# R7FA4T1BB register map
Vendor: Renesas Electronics Corporation; Series: RA4; File version: 1.20.00
CPU: CM33 r0p4, little endian, MPU, FPU, VTOR, 4 interrupt priority bits, 96 interrupts
Registers are 32-bit, read-write, reset 0x0 unless marked. A register's access mark holds for its fields unless they carry their own. Offsets are from the block's base; [hi:lo] are bit positions; 'fields as' and 'values as' point back to an identical list.

## POEG — Port Output Enable Module for GPT
Base 0x4008A000
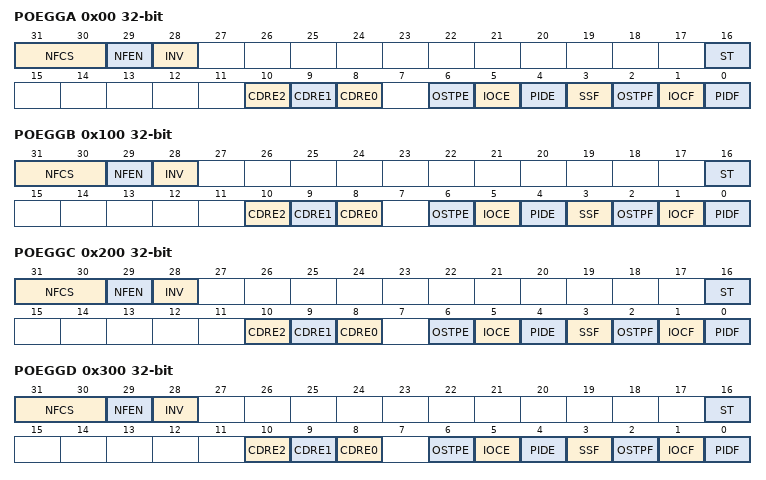
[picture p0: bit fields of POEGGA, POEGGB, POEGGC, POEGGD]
0x00 POEGGA — POEG Group A Setting Register
  [31:30] NFCS — Noise Filter Clock Select
  [29] NFEN — Noise Filter Enable
  [28] INV — GTETRGn Input Reverse
  [16] ST ro — GTETRGn Input Status Flag
  [10] CDRE2
  [9] CDRE1
  [8] CDRE0
  [6] OSTPE — Oscillation Stop Detection Enable
  [5] IOCE — Enable for GPT Output,Disable Request
  [4] PIDE — Port Input Detection Enable
  [3] SSF — Software Stop Flag
  [2] OSTPF — Oscillation Stop Detection Flag
  [1] IOCF — Detection Flag for GPT Output,Disable Request
  [0] PIDF — Port Input Detection Flag
0x100 POEGGB — POEG Group B Setting Register
  fields as POEGGA
0x200 POEGGC — POEG Group C Setting Register
  fields as POEGGA
0x300 POEGGD — POEG Group D Setting Register
  fields as POEGGA

## PSCU — Peripheral Security Control Unit
Base 0x400E0000
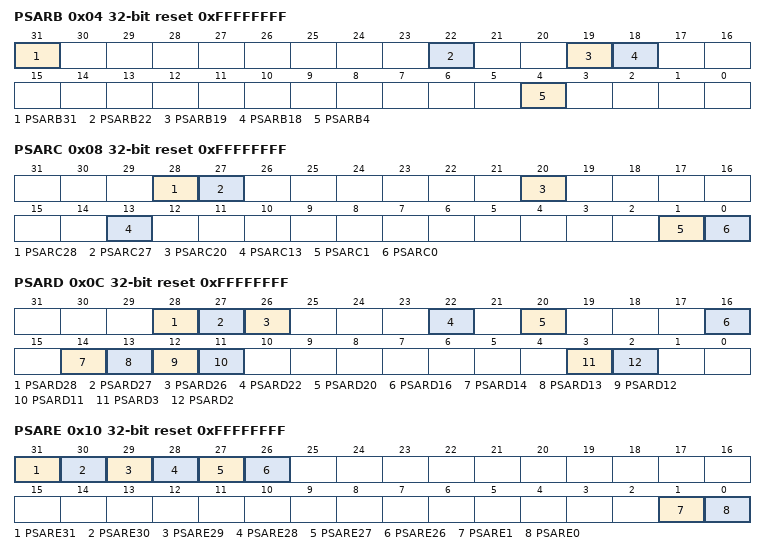
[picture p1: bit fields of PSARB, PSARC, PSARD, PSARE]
0x04 PSARB reset 0xFFFFFFFF — Peripheral Security Attribution Register B
  [31] PSARB31 — SCI0 and the MSTPCRB.MSTPB31 bit security attribution
  [22] PSARB22 — SCI9 and the MSTPCRB.MSTPB22 bit security attribution
  [19] PSARB19 — SPI0 and the MSTPCRB.MSTPB19 bit security attribution
  [18] PSARB18 — SPI1 and the MSTPCRB.MSTPB18 bit security attribution
  [4] PSARB4 — I3C and the MSTPCRB.MSTPB4 bit security attribution
0x08 PSARC reset 0xFFFFFFFF — Peripheral Security Attribution Register C
  [28] PSARC28 — TRNG and the MSTPCRC.MSTPC28 bit security attribution
  [27] PSARC27 — CANFD0 and the MSTPCRC.MSTPC27 bit security attribution
  [20] PSARC20 — TFU and the MSTPCRC.MSTPC20 bit security attribution
  [13] PSARC13 — DOC and the MSTPCRC.MSTPC13 bit security attribution
  [1] PSARC1 — CRC and the MSTPCRC.MSTPC1 bit security attribution
  [0] PSARC0 — CAC and the MSTPCRC.MSTPC0 bit security attribution
0x0C PSARD reset 0xFFFFFFFF — Peripheral Security Attribution Register D
  [28] PSARD28 — ACMPHS0 and the MSTPCRD.MSTPD28 bit security attribution
  [27] PSARD27 — ACMPHS1 and the MSTPCRD.MSTPD27 bit security attribution
  [26] PSARD26 — ACMPHS2 and the MSTPCRD.MSTPD26 bit security attribution
  [22] PSARD22 — TSN and the MSTPCRD.MSTPD22 bit security attribution
  [20] PSARD20 — DAC12 and the MSTPCRD.MSTPD20 bit security attribution
  [16] PSARD16 — ADC120 and the MSTPCRD.MSTPD16 bit security attribution
  [14] PSARD14 — POEG Group A and the MSTPCRD.MSTPD14 bit security attribution
  [13] PSARD13 — POEG Group B and the MSTPCRD.MSTPD13 bit security attribution
  [12] PSARD12 — POEG Group C and the MSTPCRD.MSTPD12 bit security attribution
  [11] PSARD11 — POEG Group D and the MSTPCRD.MSTPD11 bit security attribution
  [3] PSARD3 — AGT0 and the MSTPCRD.MSTPD3 bit security attribution
  [2] PSARD2 — AGT1 and the MSTPCRD.MSTPD2 bit security attribution
0x10 PSARE reset 0xFFFFFFFF — Peripheral Security Attribution Register E
  [31] PSARE31 — GPT0, GPT_OPS and the MSTPCRE.MSTPE31 bit security attribution
  [30] PSARE30 — GPT1 and the MSTPCRE.MSTPE30 bit security attribution
  [29] PSARE29 — GPT2 and the MSTPCRE.MSTPE29 bit security attribution
  [28] PSARE28 — GPT3 and the MSTPCRE.MSTPE28 bit security attribution
  [27] PSARE27 — GPT4 and the MSTPCRE.MSTPE27 bit security attribution
  [26] PSARE26 — GPT5 and the MSTPCRE.MSTPE26 bit security attribution
  [1] PSARE1 — IWDT security attribution
  [0] PSARE0 — WDT security attribution
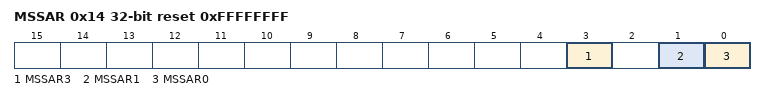
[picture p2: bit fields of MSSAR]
0x14 MSSAR reset 0xFFFFFFFF — Module Stop Security Attribution Register
  [3] MSSAR3 — The MSTPCRA.MSTPA0 bit security attribution
  [1] MSSAR1 — The MSTPCRA.MSTPA22 bit security attribution
  [0] MSSAR0 — The MSTPCRC.MSTPC14 bit security attribution
0x18 CFSAMONA (reset mask 0xFF007FFF) — Code Flash Security Attribution Register A
  [23:15] CFS2 — Code Flash Secure area 2
0x1C CFSAMONB (reset mask 0xFF0003FF) — Code Flash Security Attribution Register B
  [23:10] CFS1 — Code Flash Secure area 1
0x20 DFSAMON reset 0xFC00 — Data Flash Security Attribution Register
  [15:10] DFS — Data flash Secure area
0x24 SSAMONA reset 0x1FE000 — SRAM Security Attribution Register A
  [20:13] SS2 — SRAM Secure area 2
0x28 SSAMONB reset 0x1FFC00 — SRAM Security Attribution Register B
  [20:10] SS1 — SRAM secure area 1
